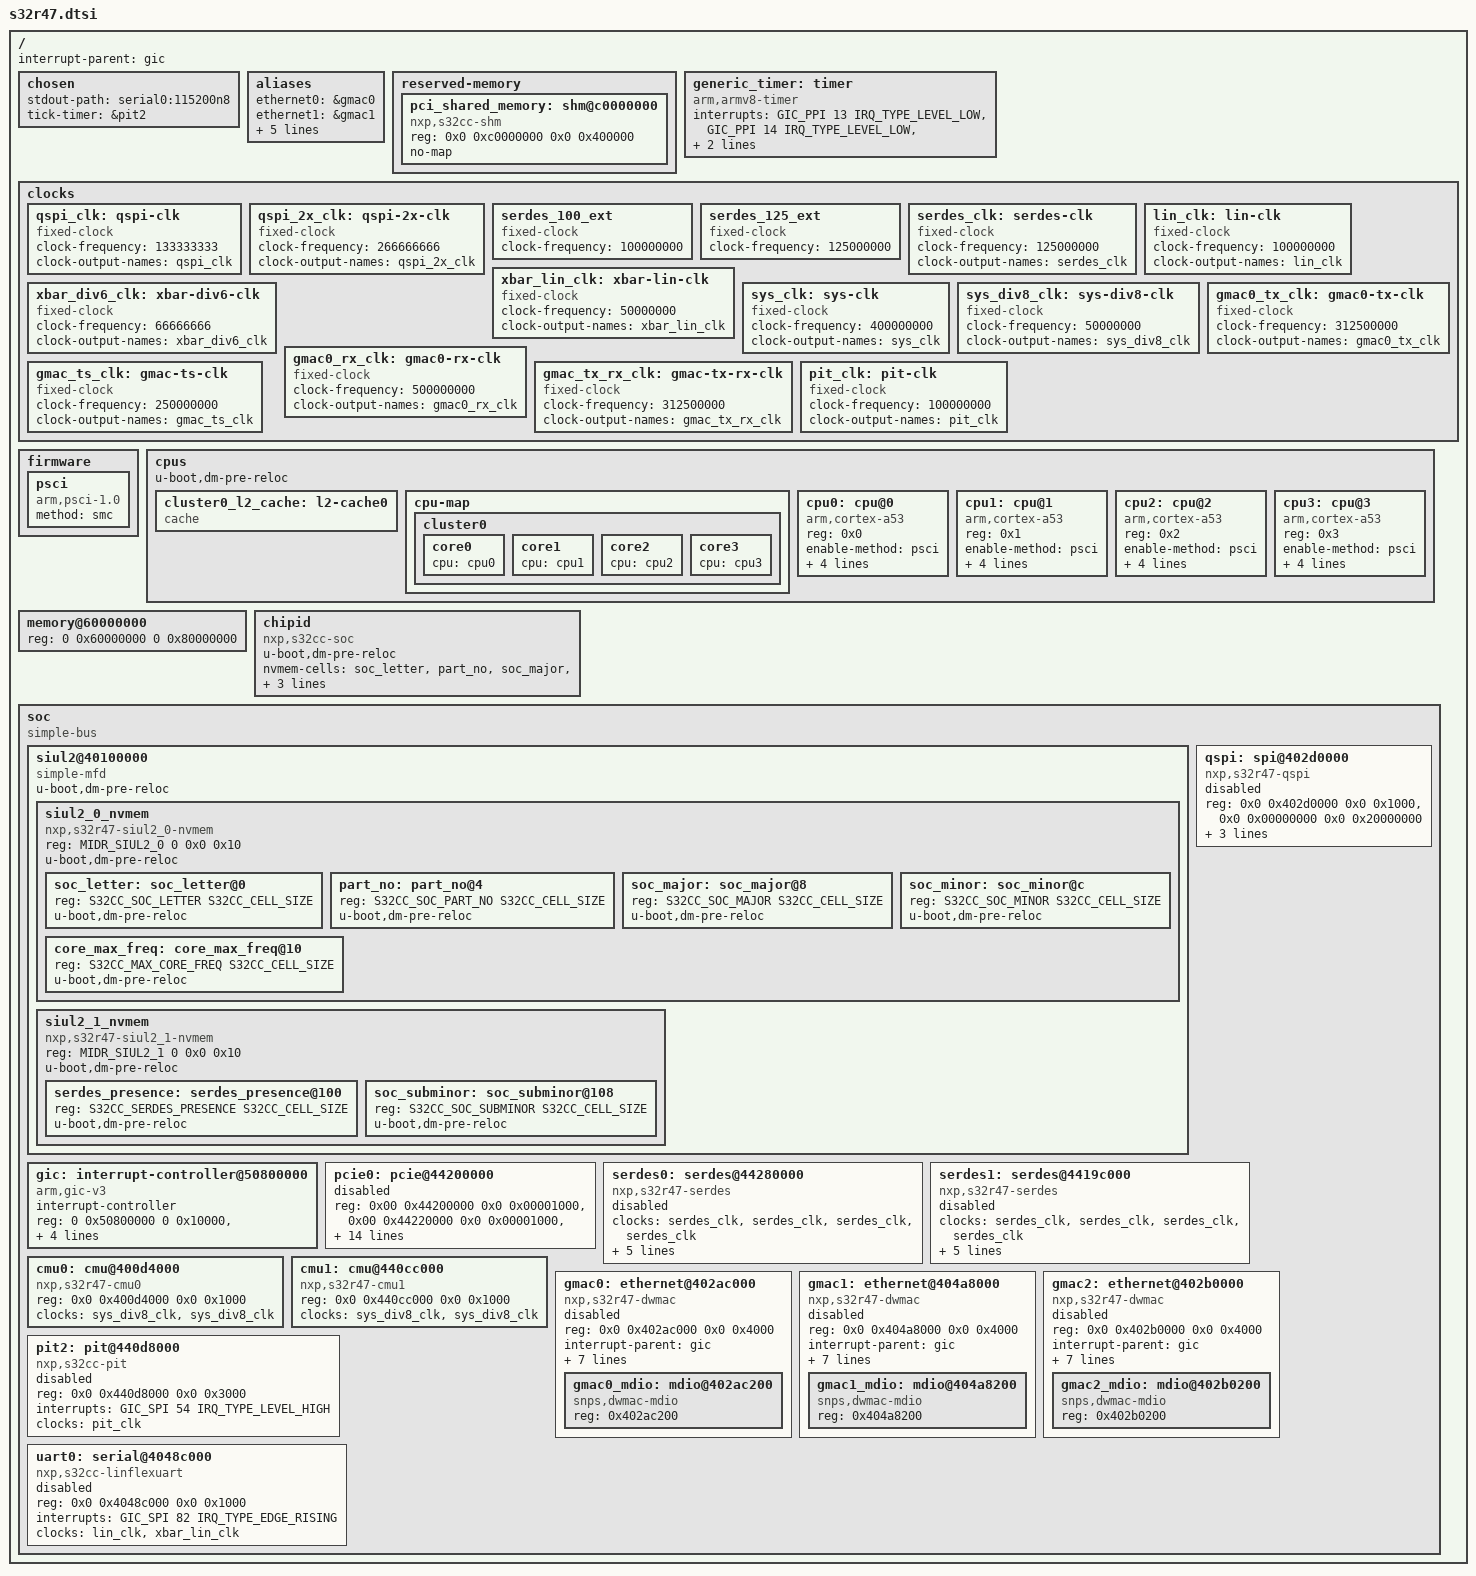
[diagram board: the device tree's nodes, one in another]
// SPDX-License-Identifier: (GPL-2.0+ OR BSD-3-Clause)
/*
 * Device Tree Include file for NXP R47 SoC.
 *
 * Copyright 2025 NXP
 */

#include <dt-bindings/interrupt-controller/arm-gic.h>
#include <dt-bindings/interrupt-controller/irq.h>
#include <dt-bindings/memory/s32-siul2.h>
#include <dt-bindings/nvmem/s32cc-siul2-nvmem.h>
#include <dt-bindings/phy/phy.h>

/dts-v1/;

/ {
	interrupt-parent = <&gic>;
	#address-cells = <2>;
	#size-cells = <2>;

	chosen {
		stdout-path = "serial0:115200n8";
		tick-timer = &pit2;
	};

	aliases {
		ethernet0 = &gmac0;
		ethernet1 = &gmac1;
		ethernet2 = &gmac2;
		pci0 = &pcie0;
		serial0 = &uart0;
		serdes0 = &serdes0;
		serdes1 = &serdes1;
	};

	reserved-memory {
		#address-cells = <2>;
		#size-cells = <2>;
		ranges;

		/* 4Mb shared memory for PCIe shared mem transfers, EP mode */
		pci_shared_memory: shm@c0000000 {
			compatible = "nxp,s32cc-shm";
			reg = <0x0 0xc0000000 0x0 0x400000>;
			no-map;
		};
	};

	generic_timer: timer {
		compatible = "arm,armv8-timer";
		interrupts = <GIC_PPI 13 IRQ_TYPE_LEVEL_LOW>,
			     <GIC_PPI 14 IRQ_TYPE_LEVEL_LOW>,
			     <GIC_PPI 11 IRQ_TYPE_LEVEL_LOW>,
			     <GIC_PPI 10 IRQ_TYPE_LEVEL_LOW>;
	};

	clocks {
		qspi_clk: qspi-clk {
			compatible = "fixed-clock";
			clock-frequency = <133333333>;
			clock-output-names = "qspi_clk";
			#clock-cells = <0>;
		};

		qspi_2x_clk: qspi-2x-clk {
			compatible = "fixed-clock";
			clock-frequency = <266666666>;
			clock-output-names = "qspi_2x_clk";
			#clock-cells = <0>;
		};

		serdes_100_ext: serdes_100_ext {
			compatible = "fixed-clock";
			clock-frequency = <100000000>;
			#clock-cells = <0>;
		};

		serdes_125_ext: serdes_125_ext {
			compatible = "fixed-clock";
			clock-frequency = <125000000>;
			#clock-cells = <0>;
		};

		serdes_clk: serdes-clk {
			compatible = "fixed-clock";
			clock-frequency = <125000000>;
			clock-output-names = "serdes_clk";
			#clock-cells = <0>;
		};

		lin_clk: lin-clk {
			compatible = "fixed-clock";
			clock-frequency = <100000000>;
			clock-output-names = "lin_clk";
			#clock-cells = <0>;
		};

		xbar_lin_clk: xbar-lin-clk {
			compatible = "fixed-clock";
			clock-frequency = <50000000>;
			clock-output-names = "xbar_lin_clk";
			#clock-cells = <0>;
		};

		xbar_div6_clk: xbar-div6-clk {
			compatible = "fixed-clock";
			clock-frequency = <66666666>;
			clock-output-names = "xbar_div6_clk";
			#clock-cells = <0>;
		};

		sys_clk: sys-clk {
			compatible = "fixed-clock";
			clock-frequency = <400000000>;
			clock-output-names = "sys_clk";
			#clock-cells = <0>;
		};

		sys_div8_clk: sys-div8-clk {
			compatible = "fixed-clock";
			clock-frequency = <50000000>;
			clock-output-names = "sys_div8_clk";
			#clock-cells = <0>;
		};

		gmac0_tx_clk: gmac0-tx-clk {
			compatible = "fixed-clock";
			clock-frequency = <312500000>;
			clock-output-names = "gmac0_tx_clk";
			#clock-cells = <0>;
		};

		gmac0_rx_clk: gmac0-rx-clk {
			compatible = "fixed-clock";
			clock-frequency = <500000000>;
			clock-output-names = "gmac0_rx_clk";
			#clock-cells = <0>;
		};

		gmac_ts_clk: gmac-ts-clk {
			compatible = "fixed-clock";
			clock-frequency = <250000000>;
			clock-output-names = "gmac_ts_clk";
			#clock-cells = <0>;
		};

		gmac_tx_rx_clk: gmac-tx-rx-clk {
			compatible = "fixed-clock";
			clock-frequency = <312500000>;
			clock-output-names = "gmac_tx_rx_clk";
			#clock-cells = <0>;
		};

		pit_clk: pit-clk {
			compatible = "fixed-clock";
			clock-frequency = <100000000>;
			clock-output-names = "pit_clk";
			#clock-cells = <0>;
		};
	};

	firmware {
		psci {
			compatible = "arm,psci-1.0";
			method = "smc";
		};
	};

	cpus {
		#address-cells = <1>;
		#size-cells = <0>;
		u-boot,dm-pre-reloc;

		cluster0_l2_cache: l2-cache0 {
			compatible = "cache";
		};

		cpu-map {
			cluster0 {
				core0 {
					cpu = <&cpu0>;
				};
				core1 {
					cpu = <&cpu1>;
				};
				core2 {
					cpu = <&cpu2>;
				};
				core3 {
					cpu = <&cpu3>;
				};
			};
		};

		cpu0: cpu@0 {
			device_type = "cpu";
			compatible = "arm,cortex-a53";
			reg = <0x0>;
			enable-method = "psci";
			next-level-cache = <&cluster0_l2_cache>;

			nvmem-cells = <&core_max_freq>;
			nvmem-cell-names = "core_max_freq";
			u-boot,dm-pre-reloc;
		};

		cpu1: cpu@1 {
			device_type = "cpu";
			compatible = "arm,cortex-a53";
			reg = <0x1>;
			enable-method = "psci";
			next-level-cache = <&cluster0_l2_cache>;

			nvmem-cells = <&core_max_freq>;
			nvmem-cell-names = "core_max_freq";
			u-boot,dm-pre-reloc;
		};

		cpu2: cpu@2 {
			device_type = "cpu";
			compatible = "arm,cortex-a53";
			reg = <0x2>;
			enable-method = "psci";
			next-level-cache = <&cluster0_l2_cache>;

			nvmem-cells = <&core_max_freq>;
			nvmem-cell-names = "core_max_freq";
			u-boot,dm-pre-reloc;
		};

		cpu3: cpu@3 {
			device_type = "cpu";
			compatible = "arm,cortex-a53";
			reg = <0x3>;
			enable-method = "psci";
			next-level-cache = <&cluster0_l2_cache>;

			nvmem-cells = <&core_max_freq>;
			nvmem-cell-names = "core_max_freq";
			u-boot,dm-pre-reloc;
		};
	};

	memory@60000000 {
		device_type = "memory";
		reg = <0 0x60000000 0 0x80000000>;
	};

	chipid: chipid {
		u-boot,dm-pre-reloc;
		compatible = "nxp,s32cc-soc";
		nvmem-cells = <&soc_letter>, <&part_no>,
			      <&soc_major>, <&soc_minor>, <&soc_subminor>;
		nvmem-cell-names = "soc_letter", "part_no",
				   "soc_major", "soc_minor", "soc_subminor";
	};

	soc: soc {
		compatible = "simple-bus";
		#address-cells = <2>;
		#size-cells = <2>;
		ranges = <0x0 0x0 0x0 0x0 0x0 0x20000000>,
			 <0x0 0x22C00000 0x0 0x22C00000 0x0 0x4000>,
			 <0x0 0x40000000 0x0 0x40000000 0x0 0x14000000>,
			 <0x48 0x0 0x48 0x0 0x8 0x0>,
			 <0x58 0x0 0x58 0x0 0x8 0x0>;

		siul2@40100000 {
			compatible = "simple-mfd";
			u-boot,dm-pre-reloc;
			#address-cells = <2>;
			#size-cells = <2>;

			/* MIDR */
			ranges = <MIDR_SIUL2_0 0 0x0 0x40100000 0x0 0x10>,
				 <MIDR_SIUL2_1 0 0x0 0x44190000 0x0 0x10>;

			siul2_0_nvmem: siul2_0_nvmem {
				reg = <MIDR_SIUL2_0 0 0x0 0x10>;
				#address-cells = <1>;
				#size-cells = <1>;

				compatible = "nxp,s32r47-siul2_0-nvmem";
				u-boot,dm-pre-reloc;

				soc_letter: soc_letter@0 {
					reg = <S32CC_SOC_LETTER S32CC_CELL_SIZE>;
					u-boot,dm-pre-reloc;
				};

				part_no: part_no@4 {
					reg = <S32CC_SOC_PART_NO S32CC_CELL_SIZE>;
					u-boot,dm-pre-reloc;
				};

				soc_major: soc_major@8 {
					reg = <S32CC_SOC_MAJOR S32CC_CELL_SIZE>;
					u-boot,dm-pre-reloc;
				};

				soc_minor: soc_minor@c {
					reg = <S32CC_SOC_MINOR S32CC_CELL_SIZE>;
					u-boot,dm-pre-reloc;
				};

				core_max_freq: core_max_freq@10 {
					reg = <S32CC_MAX_CORE_FREQ S32CC_CELL_SIZE>;
					u-boot,dm-pre-reloc;
				};
			};

			siul2_1_nvmem: siul2_1_nvmem {
				reg = <MIDR_SIUL2_1 0 0x0 0x10>;
				#address-cells = <1>;
				#size-cells = <1>;

				compatible = "nxp,s32r47-siul2_1-nvmem";
				u-boot,dm-pre-reloc;

				serdes_presence: serdes_presence@100 {
					reg = <S32CC_SERDES_PRESENCE S32CC_CELL_SIZE>;
					u-boot,dm-pre-reloc;
				};

				soc_subminor: soc_subminor@108 {
					reg = <S32CC_SOC_SUBMINOR S32CC_CELL_SIZE>;
					u-boot,dm-pre-reloc;
				};
			};
		};

		gic: interrupt-controller@50800000 {
			compatible = "arm,gic-v3";
			#interrupt-cells = <3>;
			#address-cells = <2>;
			#size-cells = <2>;
			interrupt-controller;
			reg = <0 0x50800000 0 0x10000>, /* GIC Dist */
			      <0 0x50880000 0 0x80000>, /* GICR (RD_base + SGI_base) */
			      <0 0x50400000 0 0x2000>, /* GICC */
			      <0 0x50410000 0 0x2000>, /* GICH */
			      <0 0x50420000 0 0x2000>; /* GICV */
			interrupts = <GIC_PPI 9 IRQ_TYPE_LEVEL_HIGH>;
		};

		qspi: spi@402d0000 {
			compatible = "nxp,s32r47-qspi", "nxp,s32cc-qspi";
			#address-cells = <1>;
			#size-cells = <0>;
			reg = <0x0 0x402d0000 0x0 0x1000>,
			      <0x0 0x00000000 0x0 0x20000000>;
			reg-names = "QuadSPI", "QuadSPI-memory";
			clock-names = "qspi_en", "qspi";
			clocks = <&qspi_clk>, <&qspi_clk>;
			spi-max-frequency = <133333333>;
			spi-num-chipselects = <1>;
			status = "disabled";
		};

		pcie0: pcie@44200000 {
			reg = <0x00 0x44200000 0x0 0x00001000>,   /* dbi registers */
			       <0x00 0x44220000 0x0 0x00001000>,   /* dbi2 registers */
			       <0x00 0x44260000 0x0 0x00001000>,   /* atu registers */
			       <0x00 0x44270000 0x0 0x00001000>,   /* dma registers */
			       <0x00 0x44281000 0x0 0x000000f8>,   /* ctrl registers */
			       /* RC configuration space, 4KB each for cfg0 and cfg1
					* at the end of the outbound memory map
					*/
			       <0x00 0x53ffe000 0x0 0x00002000>,
			       /* 16MB EP addr space */
			       <0x00 0x53000000 0x0 0x01000000>;
			reg-names = "dbi", "dbi2", "atu", "dma", "ctrl",
				    "config", "addr_space";
			#address-cells = <3>;
			#size-cells = <2>;

			device_type = "pci";
			device_id = <0>;

			nxp,phy-mode = "crns";
			num-lanes = <2>;

			/* Root Complex */
			bus-range = <0x0 0xff>;
			ranges =
				/* downstream I/O, 64KB and aligned naturally just
				 * before the config space to minimize fragmentation
				 */
				<0x81000000 0x0 0x00000000 0x00 0x53fe0000 0x0 0x00010000>,
				/* non-prefetchable memory, with best case size and
				 * alignment
				 */
				<0x82000000 0x0 0x00000000 0x00 0x53000000 0x0 0x00FFE000>;

			pcie_device_id = <0x5D80>;

			/* End Point */
			shared-mem = <&pci_shared_memory>;

			nvmem-cell-names = "serdes_presence";
			nvmem-cells = <&serdes_presence>;

			auto-config-bars;

			status = "disabled";
		};

		/* PCIE_ENET - PCIe & GMAC0 */
		serdes0: serdes@44280000 {
			#phy-cells = <3>;
			compatible = "nxp,s32r47-serdes";
			clocks = <&serdes_clk>, <&serdes_clk>,
				<&serdes_clk>, <&serdes_clk>;
			clock-names = "axi", "aux", "apb", "ref";
			#address-cells = <3>;
			#size-cells = <2>;
			num-lanes = <2>;
			reg = <0x0 0x44280000 0x0 0x108>,
			      <0x0 0x44283008 0x0 0x10>,
			      <0x0 0x44282000 0x0 0x800>,
			      <0x0 0x44282800 0x0 0x800>;
			reg-names = "ss_pcie", "pcie_phy", "xpcs0", "xpcs1";
			status = "disabled";
		};

		/* PCIE_APB_ENET - 1 GMAC's, 1 PCIE */
		serdes1: serdes@4419c000 {
			#phy-cells = <3>;
			compatible = "nxp,s32r47-serdes";
			clocks = <&serdes_clk>, <&serdes_clk>,
				<&serdes_clk>, <&serdes_clk>;
			clock-names = "axi", "aux", "apb", "ref";
			#address-cells = <3>;
			#size-cells = <2>;
			num-lanes = <2>;
			reg = <0x0 0x4419c000 0x0 0x108>,
			      <0x0 0x4419f008 0x0 0x10>,
			      <0x0 0x4419e000 0x0 0x800>,
			      <0x0 0x4419e800 0x0 0x800>;
			reg-names = "ss_pcie", "pcie_phy", "xpcs0", "xpcs1";
			status = "disabled";
		};

		cmu0: cmu@400d4000 {
			reg = <0x0 0x400d4000 0x0 0x1000>;
			compatible = "nxp,s32r47-cmu0";
			clocks = <&sys_div8_clk>,
				<&sys_div8_clk>;
			status = "okay";
		};

		cmu1: cmu@440cc000 {
			reg = <0x0 0x440cc000 0x0 0x1000>;
			compatible = "nxp,s32r47-cmu1";
			clocks = <&sys_div8_clk>,
				<&sys_div8_clk>;
			status = "okay";
		};

		gmac0: ethernet@402ac000 {
			compatible = "nxp,s32r47-dwmac";
			reg = <0x0 0x402ac000 0x0 0x4000>;
			interrupt-parent = <&gic>;
			interrupts = <GIC_SPI 215 IRQ_TYPE_LEVEL_HIGH>;
			interrupt-names = "macirq";
			tx-fifo-depth = <20480>;
			rx-fifo-depth = <20480>;
			status = "disabled";
			phy-names = "gmac_xpcs";
			phys = <&serdes0 PHY_TYPE_XPCS 0 1>;
			phy-mode = "sgmii";
			clocks = <&sys_clk>,
				 <&sys_clk>,
				 <&gmac_tx_rx_clk>,
				 <&gmac_tx_rx_clk>,
				 <&gmac_ts_clk>;
			clock-names = "stmmaceth", "pclk",
				      "tx_sgmii", "rx_sgmii",
				      "ptp_ref";
			#address-cells = <1>;
			#size-cells = <0>;

			gmac0_mdio: mdio@402ac200 {
				compatible = "snps,dwmac-mdio";
				#address-cells = <1>;
				#size-cells = <0>;
				reg = <0x402ac200>;
			};
		};

		gmac1: ethernet@404a8000 {
			compatible = "nxp,s32r47-dwmac";
			reg = <0x0 0x404a8000 0x0 0x4000>;
			interrupt-parent = <&gic>;
			interrupts = <GIC_SPI 220 IRQ_TYPE_LEVEL_HIGH>;
			interrupt-names = "macirq";
			tx-fifo-depth = <20480>;
			rx-fifo-depth = <20480>;
			status = "disabled";
			phy-names = "gmac_xpcs";
			phys = <&serdes1 PHY_TYPE_XPCS 1 0>;
			phy-mode = "sgmii";
			clocks = <&sys_clk>,
				 <&sys_clk>,
				 <&gmac_tx_rx_clk>,
				 <&gmac_tx_rx_clk>,
				 <&gmac_ts_clk>;
			clock-names = "stmmaceth", "pclk",
				      "tx_sgmii", "rx_sgmii",
				      "ptp_ref";
			#address-cells = <1>;
			#size-cells = <0>;

			gmac1_mdio: mdio@404a8200 {
				#address-cells = <1>;
				#size-cells = <0>;
				compatible = "snps,dwmac-mdio";
				reg = <0x404a8200>;
			};
		};

		gmac2: ethernet@402b0000 {
			compatible = "nxp,s32r47-dwmac";
			reg = <0x0 0x402b0000 0x0 0x4000>;
			interrupt-parent = <&gic>;
			interrupts = <GIC_SPI 225 IRQ_TYPE_LEVEL_HIGH>;
			interrupt-names = "macirq";
			tx-fifo-depth = <20480>;
			rx-fifo-depth = <20480>;
			status = "disabled";
			phy-names = "gmac_xpcs";
			phys = <&serdes1 PHY_TYPE_XPCS 1 1>;
			phy-mode = "sgmii";
			clocks = <&sys_clk>,
				 <&sys_clk>,
				 <&gmac_tx_rx_clk>,
				 <&gmac_tx_rx_clk>,
				 <&gmac_ts_clk>;
			clock-names = "stmmaceth", "pclk",
				      "tx_sgmii", "rx_sgmii",
				      "ptp_ref";
			#address-cells = <1>;
			#size-cells = <0>;

			gmac2_mdio: mdio@402b0200 {
				#address-cells = <1>;
				#size-cells = <0>;
				compatible = "snps,dwmac-mdio";
				reg = <0x402b0200>;
			};
		};

		pit2: pit@440d8000 {
			compatible = "nxp,s32cc-pit";
			reg = <0x0 0x440d8000 0x0 0x3000>;
			interrupts = <GIC_SPI 54 IRQ_TYPE_LEVEL_HIGH>;
			clocks = <&pit_clk>;
			clock-names = "pit";
			status = "disabled";
		};

		uart0: serial@4048c000 {
			compatible = "nxp,s32cc-linflexuart",
				     "fsl,s32v234-linflexuart";
			reg = <0x0 0x4048c000 0x0 0x1000>;
			interrupts = <GIC_SPI 82 IRQ_TYPE_EDGE_RISING>;
			clocks = <&lin_clk>, <&xbar_lin_clk>;
			clock-names = "lin", "ipg";
			status = "disabled";
		};
	};
};
